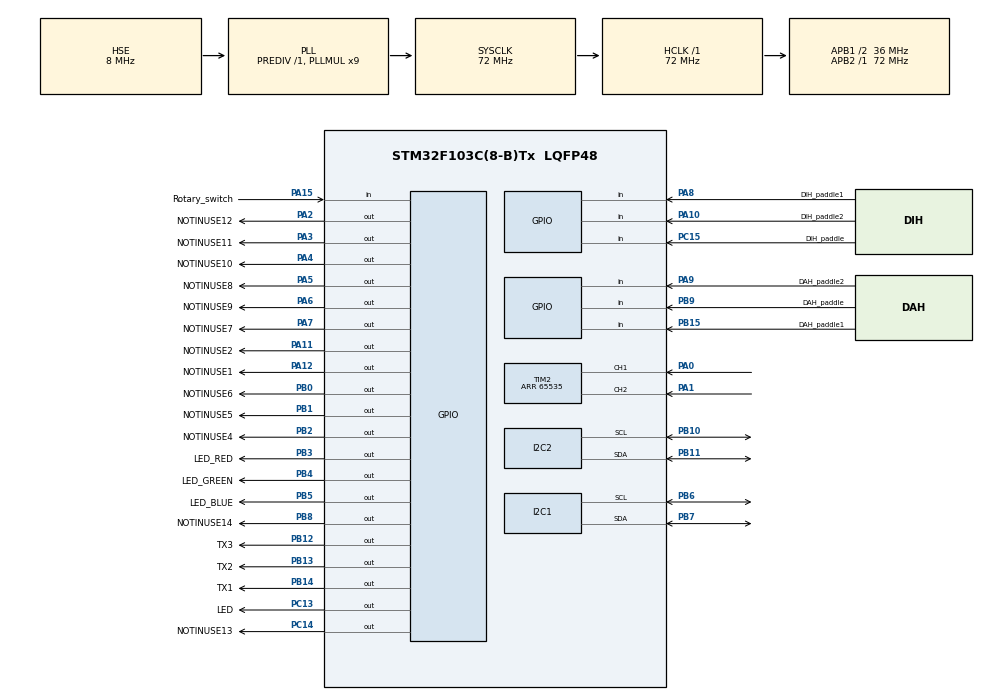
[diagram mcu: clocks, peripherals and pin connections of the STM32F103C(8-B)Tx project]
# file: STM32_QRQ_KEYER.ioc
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FREERTOS.Tasks01=defaultTask,24,128,StartDefaultTask,Default,NULL,Dynamic,NULL,NULL;myTask02,24,128,StartTask02,Default,NULL,Dynamic,NULL,NULL
FREERTOS.configTOTAL_HEAP_SIZE=4072
I2C1.I2C_Mode=I2C_Fast
I2C2.I2C_Mode=I2C_Fast
Mcu.Family=STM32F1
Mcu.Name=STM32F103C(8-B)Tx
Mcu.Package=LQFP48
NVIC.PriorityGroup=NVIC_PRIORITYGROUP_4
NVIC.TIM1_UP_IRQn=true\:0\:0\:false\:false\:true\:false\:false\:true
NVIC.TIM4_IRQn=true\:0\:0\:false\:false\:true\:true\:true\:true
NVIC.TimeBase=TIM1_UP_IRQn
NVIC.TimeBaseIP=TIM1
PA0-WKUP.GPIO_PuPd=GPIO_PULLUP
PA0-WKUP.Signal=S_TIM2_CH1_ETR
PA1.GPIO_PuPd=GPIO_PULLUP
PA1.Signal=S_TIM2_CH2
PA10.GPIO_Label=DIH_paddle2
PA10.GPIO_PuPd=GPIO_PULLUP
PA10.Signal=GPIO_Input
PA11.GPIO_Label=NOTINUSE2
PA11.GPIO_PuPd=GPIO_PULLDOWN
PA11.Signal=GPIO_Output
PA12.GPIO_Label=NOTINUSE1
PA12.GPIO_PuPd=GPIO_PULLDOWN
PA12.Signal=GPIO_Output
PA13.Mode=Serial_Wire
PA13.Signal=SYS_JTMS-SWDIO
PA14.Mode=Serial_Wire
PA14.Signal=SYS_JTCK-SWCLK
PA15.GPIO_Label=Rotary_switch
PA15.GPIO_PuPd=GPIO_PULLDOWN
PA15.Signal=GPIO_Input
PA2.GPIO_Label=NOTINUSE12
PA2.GPIO_ModeDefaultOutputPP=GPIO_MODE_OUTPUT_PP
PA2.GPIO_PuPd=GPIO_PULLDOWN
PA2.Signal=GPIO_Output
PA3.GPIO_Label=NOTINUSE11
PA3.GPIO_PuPd=GPIO_PULLDOWN
PA3.Signal=GPIO_Output
PA4.GPIO_Label=NOTINUSE10
PA4.GPIO_PuPd=GPIO_PULLDOWN
PA4.Signal=GPIO_Output
PA5.GPIO_Label=NOTINUSE8
PA5.GPIO_PuPd=GPIO_PULLDOWN
PA5.Signal=GPIO_Output
PA6.GPIO_Label=NOTINUSE9
PA6.GPIO_PuPd=GPIO_PULLDOWN
PA6.Signal=GPIO_Output
PA7.GPIO_Label=NOTINUSE7
PA7.GPIO_PuPd=GPIO_PULLDOWN
PA7.Signal=GPIO_Output
PA8.GPIO_Label=DIH_paddle1
PA8.GPIO_PuPd=GPIO_PULLUP
PA8.Signal=GPIO_Input
PA9.GPIO_Label=DAH_paddle2
PA9.GPIO_PuPd=GPIO_PULLUP
PA9.Signal=GPIO_Input
PB0.GPIO_Label=NOTINUSE6
PB0.GPIO_PuPd=GPIO_PULLDOWN
PB0.Signal=GPIO_Output
PB1.GPIO_Label=NOTINUSE5
PB1.GPIO_PuPd=GPIO_PULLDOWN
PB1.Signal=GPIO_Output
PB10.Mode=I2C
PB10.Signal=I2C2_SCL
PB11.Mode=I2C
PB11.Signal=I2C2_SDA
PB12.GPIO_Label=TX3
PB12.GPIO_PuPd=GPIO_PULLDOWN
PB12.Signal=GPIO_Output
PB13.GPIO_Label=TX2
PB13.GPIO_PuPd=GPIO_PULLDOWN
PB13.Signal=GPIO_Output
PB14.GPIO_Label=TX1
PB14.GPIO_PuPd=GPIO_PULLDOWN
PB14.Signal=GPIO_Output
PB15.GPIO_Label=DAH_paddle1
PB15.GPIO_PuPd=GPIO_PULLUP
PB15.Signal=GPIO_Input
PB2.GPIO_Label=NOTINUSE4
PB2.GPIO_PuPd=GPIO_PULLDOWN
PB2.Signal=GPIO_Output
PB3.GPIO_Label=LED_RED
PB3.GPIO_PuPd=GPIO_PULLUP
PB3.PinState=GPIO_PIN_SET
PB3.Signal=GPIO_Output
PB4.GPIO_Label=LED_GREEN
PB4.GPIO_PuPd=GPIO_PULLUP
PB4.PinState=GPIO_PIN_SET
PB4.Signal=GPIO_Output
PB5.GPIO_Label=LED_BLUE
PB5.GPIO_PuPd=GPIO_PULLUP
PB5.PinState=GPIO_PIN_SET
PB5.Signal=GPIO_Output
PB6.Mode=I2C
PB6.Signal=I2C1_SCL
PB7.Mode=I2C
PB7.Signal=I2C1_SDA
PB8.GPIO_Label=NOTINUSE14
PB8.GPIO_PuPd=GPIO_PULLDOWN
PB8.Signal=GPIO_Output
PB9.GPIO_Label=DAH_paddle
PB9.GPIO_PuPd=GPIO_PULLUP
PB9.Signal=GPIO_Input
PC13-TAMPER-RTC.GPIO_Label=LED
PC13-TAMPER-RTC.PinState=GPIO_PIN_SET
PC13-TAMPER-RTC.Signal=GPIO_Output
PC14-OSC32_IN.GPIO_Label=NOTINUSE13
PC14-OSC32_IN.GPIO_PuPd=GPIO_PULLDOWN
PC14-OSC32_IN.Signal=GPIO_Output
PC15-OSC32_OUT.GPIO_Label=DIH_paddle
PC15-OSC32_OUT.GPIO_PuPd=GPIO_PULLUP
PC15-OSC32_OUT.Signal=GPIO_Input
PD0-OSC_IN.Mode=HSE-External-Oscillator
PD0-OSC_IN.Signal=RCC_OSC_IN
PD1-OSC_OUT.Mode=HSE-External-Oscillator
PD1-OSC_OUT.Signal=RCC_OSC_OUT
ProjectManager.HeapSize=0x200
ProjectManager.StackSize=0x400
ProjectManager.TargetToolchain=STM32CubeIDE
RCC.AHBFreq_Value=72000000
RCC.APB1CLKDivider=RCC_HCLK_DIV2
RCC.APB1Freq_Value=36000000
RCC.APB1TimFreq_Value=72000000
RCC.APB2Freq_Value=72000000
RCC.APB2TimFreq_Value=72000000
RCC.HCLKFreq_Value=72000000
RCC.PLLMUL=RCC_PLL_MUL9
RCC.PLLSourceVirtual=RCC_PLLSOURCE_HSE
RCC.SYSCLKFreq_VALUE=72000000
RCC.SYSCLKSource=RCC_SYSCLKSOURCE_PLLCLK
RCC.USBFreq_Value=72000000
SH.S_TIM2_CH1_ETR.0=TIM2_CH1,Encoder_Interface
SH.S_TIM2_CH2.0=TIM2_CH2,Encoder_Interface
TIM2.EncoderMode=TIM_ENCODERMODE_TI12
TIM2.Period=65535
TIM2.TIM_MasterOutputTrigger=TIM_TRGO_UPDATE
TIM4.Channel-Output\ Compare1\ No\ Output=TIM_CHANNEL_1
TIM4.Period=97
TIM4.Prescaler=72
TIM4.TIM_MasterOutputTrigger=TIM_TRGO_UPDATE
VP_FREERTOS_VS_CMSIS_V2.Mode=CMSIS_V2
VP_SYS_VS_tim1.Mode=TIM1
VP_TIM4_VS_no_output1.Mode=Output Compare1 No Output
board=custom

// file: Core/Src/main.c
/* USER CODE BEGIN Header */
/**
  ******************************************************************************
  * @file           : main.c
  * @brief          : Main program body
  ******************************************************************************
  * @attention
  *
  * <h2><center>&copy; Copyright (c) 2020 STMicroelectronics.
  * All rights reserved.</center></h2>
  *
  * This software component is licensed by ST under BSD 3-Clause license,
  * the "License"; You may not use this file except in compliance with the
  * License. You may obtain a copy of the License at:
  *                        opensource.org/licenses/BSD-3-Clause
  *
  ******************************************************************************
  */
/* USER CODE END Header */

#include "main.h"
#include "cmsis_os.h"

/* USER CODE BEGIN Includes */

#include "fonts.h"
#include "ssd1306.h"
#include "Keyer.h"
#include "ascii.h"

/* USER CODE END Includes */

I2C_HandleTypeDef hi2c1;
I2C_HandleTypeDef hi2c2;

TIM_HandleTypeDef htim2;
TIM_HandleTypeDef htim4;

/* Definitions for defaultTask */
osThreadId_t defaultTaskHandle;
const osThreadAttr_t defaultTask_attributes = {
  .name = "defaultTask",
  .priority = (osPriority_t) osPriorityNormal,
  .stack_size = 128 * 4
};
/* Definitions for myTask02 */
osThreadId_t myTask02Handle;
const osThreadAttr_t myTask02_attributes = {
  .name = "myTask02",
  .priority = (osPriority_t) osPriorityNormal,
  .stack_size = 128 * 4
};

void SystemClock_Config(void);
static void MX_GPIO_Init(void);
static void MX_I2C1_Init(void);
static void MX_TIM4_Init(void);
static void MX_TIM2_Init(void);
static void MX_I2C2_Init(void);
void StartDefaultTask(void *argument);
void StartTask02(void *argument);

int main(void)
{

  /* MCU Configuration--------------------------------------------------------*/

  /* Reset of all peripherals, Initializes the Flash interface and the Systick. */
  HAL_Init();

  /* Configure the system clock */
  SystemClock_Config();

  /* Initialize all configured peripherals */
  MX_GPIO_Init();
  MX_I2C1_Init();
  MX_TIM4_Init();
  MX_TIM2_Init();
  MX_I2C2_Init();
  /* USER CODE BEGIN 2 */
  HAL_TIM_Base_Start_IT(&htim4);
  HAL_TIM_Base_Start(&htim2);
  TIM2->CNT = 30000;
  SSD1306_Init();  // initialise
  SSD1306_Clear();

  hjhKeyerSetup();

  /* USER CODE END 2 */

  /* Init scheduler */
  osKernelInitialize();

  /* Create the thread(s) */
  /* creation of defaultTask */
  defaultTaskHandle = osThreadNew(StartDefaultTask, NULL, &defaultTask_attributes);

  /* creation of myTask02 */
  myTask02Handle = osThreadNew(StartTask02, NULL, &myTask02_attributes);

  /* Start scheduler */
  osKernelStart();

  /* We should never get here as control is now taken by the scheduler */
  /* Infinite loop */
  while (1)
  {

  }
}

void SystemClock_Config(void)
{
  RCC_OscInitTypeDef RCC_OscInitStruct = {0};
  RCC_ClkInitTypeDef RCC_ClkInitStruct = {0};

  /** Initializes the CPU, AHB and APB busses clocks
  */
  RCC_OscInitStruct.OscillatorType = RCC_OSCILLATORTYPE_HSE;
  RCC_OscInitStruct.HSEState = RCC_HSE_ON;
  RCC_OscInitStruct.HSEPredivValue = RCC_HSE_PREDIV_DIV1;
  RCC_OscInitStruct.HSIState = RCC_HSI_ON;
  RCC_OscInitStruct.PLL.PLLState = RCC_PLL_ON;
  RCC_OscInitStruct.PLL.PLLSource = RCC_PLLSOURCE_HSE;
  RCC_OscInitStruct.PLL.PLLMUL = RCC_PLL_MUL9;
  if (HAL_RCC_OscConfig(&RCC_OscInitStruct) != HAL_OK)
  {
    Error_Handler();
  }
  /** Initializes the CPU, AHB and APB busses clocks
  */
  RCC_ClkInitStruct.ClockType = RCC_CLOCKTYPE_HCLK|RCC_CLOCKTYPE_SYSCLK
                              |RCC_CLOCKTYPE_PCLK1|RCC_CLOCKTYPE_PCLK2;
  RCC_ClkInitStruct.SYSCLKSource = RCC_SYSCLKSOURCE_PLLCLK;
  RCC_ClkInitStruct.AHBCLKDivider = RCC_SYSCLK_DIV1;
  RCC_ClkInitStruct.APB1CLKDivider = RCC_HCLK_DIV2;
  RCC_ClkInitStruct.APB2CLKDivider = RCC_HCLK_DIV1;

  if (HAL_RCC_ClockConfig(&RCC_ClkInitStruct, FLASH_LATENCY_2) != HAL_OK)
  {
    Error_Handler();
  }
}

static void MX_I2C1_Init(void)
{

  hi2c1.Instance = I2C1;
  hi2c1.Init.ClockSpeed = 400000;
  hi2c1.Init.DutyCycle = I2C_DUTYCYCLE_2;
  hi2c1.Init.OwnAddress1 = 0;
  hi2c1.Init.AddressingMode = I2C_ADDRESSINGMODE_7BIT;
  hi2c1.Init.DualAddressMode = I2C_DUALADDRESS_DISABLE;
  hi2c1.Init.OwnAddress2 = 0;
  hi2c1.Init.GeneralCallMode = I2C_GENERALCALL_DISABLE;
  hi2c1.Init.NoStretchMode = I2C_NOSTRETCH_DISABLE;
  if (HAL_I2C_Init(&hi2c1) != HAL_OK)
  {
    Error_Handler();
  }

}

static void MX_I2C2_Init(void)
{

  hi2c2.Instance = I2C2;
  hi2c2.Init.ClockSpeed = 400000;
  hi2c2.Init.DutyCycle = I2C_DUTYCYCLE_2;
  hi2c2.Init.OwnAddress1 = 0;
  hi2c2.Init.AddressingMode = I2C_ADDRESSINGMODE_7BIT;
  hi2c2.Init.DualAddressMode = I2C_DUALADDRESS_DISABLE;
  hi2c2.Init.OwnAddress2 = 0;
  hi2c2.Init.GeneralCallMode = I2C_GENERALCALL_DISABLE;
  hi2c2.Init.NoStretchMode = I2C_NOSTRETCH_DISABLE;
  if (HAL_I2C_Init(&hi2c2) != HAL_OK)
  {
    Error_Handler();
  }

}

static void MX_TIM2_Init(void)
{

  TIM_Encoder_InitTypeDef sConfig = {0};
  TIM_MasterConfigTypeDef sMasterConfig = {0};

  htim2.Instance = TIM2;
  htim2.Init.Prescaler = 0;
  htim2.Init.CounterMode = TIM_COUNTERMODE_UP;
  htim2.Init.Period = 65535;
  htim2.Init.ClockDivision = TIM_CLOCKDIVISION_DIV1;
  htim2.Init.AutoReloadPreload = TIM_AUTORELOAD_PRELOAD_DISABLE;
  sConfig.EncoderMode = TIM_ENCODERMODE_TI12;
  sConfig.IC1Polarity = TIM_ICPOLARITY_RISING;
  sConfig.IC1Selection = TIM_ICSELECTION_DIRECTTI;
  sConfig.IC1Prescaler = TIM_ICPSC_DIV1;
  sConfig.IC1Filter = 0;
  sConfig.IC2Polarity = TIM_ICPOLARITY_RISING;
  sConfig.IC2Selection = TIM_ICSELECTION_DIRECTTI;
  sConfig.IC2Prescaler = TIM_ICPSC_DIV1;
  sConfig.IC2Filter = 0;
  if (HAL_TIM_Encoder_Init(&htim2, &sConfig) != HAL_OK)
  {
    Error_Handler();
  }
  sMasterConfig.MasterOutputTrigger = TIM_TRGO_UPDATE;
  sMasterConfig.MasterSlaveMode = TIM_MASTERSLAVEMODE_DISABLE;
  if (HAL_TIMEx_MasterConfigSynchronization(&htim2, &sMasterConfig) != HAL_OK)
  {
    Error_Handler();
  }

}

static void MX_TIM4_Init(void)
{

  TIM_MasterConfigTypeDef sMasterConfig = {0};
  TIM_OC_InitTypeDef sConfigOC = {0};

  htim4.Instance = TIM4;
  htim4.Init.Prescaler = 72;
  htim4.Init.CounterMode = TIM_COUNTERMODE_UP;
  htim4.Init.Period = 97;
  htim4.Init.ClockDivision = TIM_CLOCKDIVISION_DIV1;
  htim4.Init.AutoReloadPreload = TIM_AUTORELOAD_PRELOAD_DISABLE;
  if (HAL_TIM_OC_Init(&htim4) != HAL_OK)
  {
    Error_Handler();
  }
  sMasterConfig.MasterOutputTrigger = TIM_TRGO_UPDATE;
  sMasterConfig.MasterSlaveMode = TIM_MASTERSLAVEMODE_DISABLE;
  if (HAL_TIMEx_MasterConfigSynchronization(&htim4, &sMasterConfig) != HAL_OK)
  {
    Error_Handler();
  }
  sConfigOC.OCMode = TIM_OCMODE_TIMING;
  sConfigOC.Pulse = 0;
  sConfigOC.OCPolarity = TIM_OCPOLARITY_HIGH;
  sConfigOC.OCFastMode = TIM_OCFAST_DISABLE;
  if (HAL_TIM_OC_ConfigChannel(&htim4, &sConfigOC, TIM_CHANNEL_1) != HAL_OK)
  {
    Error_Handler();
  }

}

static void MX_GPIO_Init(void)
{
  GPIO_InitTypeDef GPIO_InitStruct = {0};

  /* GPIO Ports Clock Enable */
  __HAL_RCC_GPIOC_CLK_ENABLE();
  __HAL_RCC_GPIOD_CLK_ENABLE();
  __HAL_RCC_GPIOA_CLK_ENABLE();
  __HAL_RCC_GPIOB_CLK_ENABLE();

  /*Configure GPIO pin Output Level */
  HAL_GPIO_WritePin(LED_GPIO_Port, LED_Pin, GPIO_PIN_SET);

  /*Configure GPIO pin Output Level */
  HAL_GPIO_WritePin(NOTINUSE13_GPIO_Port, NOTINUSE13_Pin, GPIO_PIN_RESET);

  /*Configure GPIO pin Output Level */
  HAL_GPIO_WritePin(GPIOA, NOTINUSE12_Pin|NOTINUSE11_Pin|NOTINUSE10_Pin|NOTINUSE8_Pin
                          |NOTINUSE9_Pin|NOTINUSE7_Pin|NOTINUSE2_Pin|NOTINUSE1_Pin, GPIO_PIN_RESET);

  /*Configure GPIO pin Output Level */
  HAL_GPIO_WritePin(GPIOB, NOTINUSE6_Pin|NOTINUSE5_Pin|NOTINUSE4_Pin|TX3_Pin
                          |TX2_Pin|TX1_Pin|NOTINUSE14_Pin, GPIO_PIN_RESET);

  /*Configure GPIO pin Output Level */
  HAL_GPIO_WritePin(GPIOB, LED_RED_Pin|LED_GREEN_Pin|LED_BLUE_Pin, GPIO_PIN_SET);

  /*Configure GPIO pin : LED_Pin */
  GPIO_InitStruct.Pin = LED_Pin;
  GPIO_InitStruct.Mode = GPIO_MODE_OUTPUT_PP;
  GPIO_InitStruct.Pull = GPIO_NOPULL;
  GPIO_InitStruct.Speed = GPIO_SPEED_FREQ_LOW;
  HAL_GPIO_Init(LED_GPIO_Port, &GPIO_InitStruct);

  /*Configure GPIO pin : NOTINUSE13_Pin */
  GPIO_InitStruct.Pin = NOTINUSE13_Pin;
  GPIO_InitStruct.Mode = GPIO_MODE_OUTPUT_PP;
  GPIO_InitStruct.Pull = GPIO_PULLDOWN;
  GPIO_InitStruct.Speed = GPIO_SPEED_FREQ_LOW;
  HAL_GPIO_Init(NOTINUSE13_GPIO_Port, &GPIO_InitStruct);

  /*Configure GPIO pin : DIH_paddle_Pin */
  GPIO_InitStruct.Pin = DIH_paddle_Pin;
  GPIO_InitStruct.Mode = GPIO_MODE_INPUT;
  GPIO_InitStruct.Pull = GPIO_PULLUP;
  HAL_GPIO_Init(DIH_paddle_GPIO_Port, &GPIO_InitStruct);

  /*Configure GPIO pins : NOTINUSE12_Pin NOTINUSE11_Pin NOTINUSE10_Pin NOTINUSE8_Pin
                           NOTINUSE9_Pin NOTINUSE7_Pin NOTINUSE2_Pin NOTINUSE1_Pin */
  GPIO_InitStruct.Pin = NOTINUSE12_Pin|NOTINUSE11_Pin|NOTINUSE10_Pin|NOTINUSE8_Pin
                          |NOTINUSE9_Pin|NOTINUSE7_Pin|NOTINUSE2_Pin|NOTINUSE1_Pin;
  GPIO_InitStruct.Mode = GPIO_MODE_OUTPUT_PP;
  GPIO_InitStruct.Pull = GPIO_PULLDOWN;
  GPIO_InitStruct.Speed = GPIO_SPEED_FREQ_LOW;
  HAL_GPIO_Init(GPIOA, &GPIO_InitStruct);

  /*Configure GPIO pins : NOTINUSE6_Pin NOTINUSE5_Pin NOTINUSE4_Pin TX3_Pin
                           TX2_Pin TX1_Pin NOTINUSE14_Pin */
  GPIO_InitStruct.Pin = NOTINUSE6_Pin|NOTINUSE5_Pin|NOTINUSE4_Pin|TX3_Pin
                          |TX2_Pin|TX1_Pin|NOTINUSE14_Pin;
  GPIO_InitStruct.Mode = GPIO_MODE_OUTPUT_PP;
  GPIO_InitStruct.Pull = GPIO_PULLDOWN;
  GPIO_InitStruct.Speed = GPIO_SPEED_FREQ_LOW;
  HAL_GPIO_Init(GPIOB, &GPIO_InitStruct);

  /*Configure GPIO pins : DAH_paddle1_Pin DAH_paddle_Pin */
  GPIO_InitStruct.Pin = DAH_paddle1_Pin|DAH_paddle_Pin;
  GPIO_InitStruct.Mode = GPIO_MODE_INPUT;
  GPIO_InitStruct.Pull = GPIO_PULLUP;
  HAL_GPIO_Init(GPIOB, &GPIO_InitStruct);

  /*Configure GPIO pins : DIH_paddle1_Pin DAH_paddle2_Pin DIH_paddle2_Pin */
  GPIO_InitStruct.Pin = DIH_paddle1_Pin|DAH_paddle2_Pin|DIH_paddle2_Pin;
  GPIO_InitStruct.Mode = GPIO_MODE_INPUT;
  GPIO_InitStruct.Pull = GPIO_PULLUP;
  HAL_GPIO_Init(GPIOA, &GPIO_InitStruct);

  /*Configure GPIO pin : Rotary_switch_Pin */
  GPIO_InitStruct.Pin = Rotary_switch_Pin;
  GPIO_InitStruct.Mode = GPIO_MODE_INPUT;
  GPIO_InitStruct.Pull = GPIO_PULLDOWN;
  HAL_GPIO_Init(Rotary_switch_GPIO_Port, &GPIO_InitStruct);

  /*Configure GPIO pins : LED_RED_Pin LED_GREEN_Pin LED_BLUE_Pin */
  GPIO_InitStruct.Pin = LED_RED_Pin|LED_GREEN_Pin|LED_BLUE_Pin;
  GPIO_InitStruct.Mode = GPIO_MODE_OUTPUT_PP;
  GPIO_InitStruct.Pull = GPIO_PULLUP;
  GPIO_InitStruct.Speed = GPIO_SPEED_FREQ_LOW;
  HAL_GPIO_Init(GPIOB, &GPIO_InitStruct);

}

void StartDefaultTask(void *argument)
{
  /* USER CODE BEGIN 5 */
  /* Infinite loop */
  for(;;)
  {
	  KeyerMain();
  }
  /* USER CODE END 5 */
}

void StartTask02(void *argument)
{
  /* USER CODE BEGIN StartTask02 */
  /* Infinite loop */
  for(;;)
  {
	  send_to_ssd1306();
  }
  /* USER CODE END StartTask02 */
}

 /**
  * @brief  Period elapsed callback in non blocking mode
  * @note   This function is called  when TIM1 interrupt took place, inside
  * HAL_TIM_IRQHandler(). It makes a direct call to HAL_IncTick() to increment
  * a global variable "uwTick" used as application time base.
  * @param  htim : TIM handle
  * @retval None
  */
void HAL_TIM_PeriodElapsedCallback(TIM_HandleTypeDef *htim)
{
  if (htim->Instance == TIM1) {
    HAL_IncTick();
  }
}

void Error_Handler(void)
{
}

/************************ (C) COPYRIGHT STMicroelectronics *****END OF FILE****/
